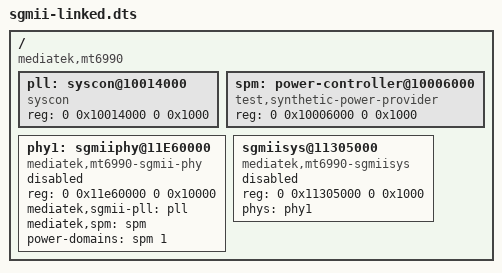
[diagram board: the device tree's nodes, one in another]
/dts-v1/;
/ {
    compatible = "mediatek,mt6990";
    #address-cells = <2>;
    #size-cells = <2>;

    pll: syscon@10014000 {
        compatible = "syscon";
        reg = <0 0x10014000 0 0x1000>;
    };
    spm: power-controller@10006000 {
        compatible = "test,synthetic-power-provider";
        reg = <0 0x10006000 0 0x1000>;
        #power-domain-cells = <1>;
    };
    phy1: sgmiiphy@11E60000 {
        compatible = "mediatek,mt6990-sgmii-phy";
        reg = <0 0x11e60000 0 0x10000>;
        #phy-cells = <0>;
        mediatek,sgmii-pll = <&pll>;
        mediatek,spm = <&spm>;
        power-domains = <&spm 1>;
        status = "disabled";
    };
    sgmiisys@11305000 {
        compatible = "mediatek,mt6990-sgmiisys";
        reg = <0 0x11305000 0 0x1000>;
        phys = <&phy1>;
        phy-names = "sgmii";
        status = "disabled";
    };
};
